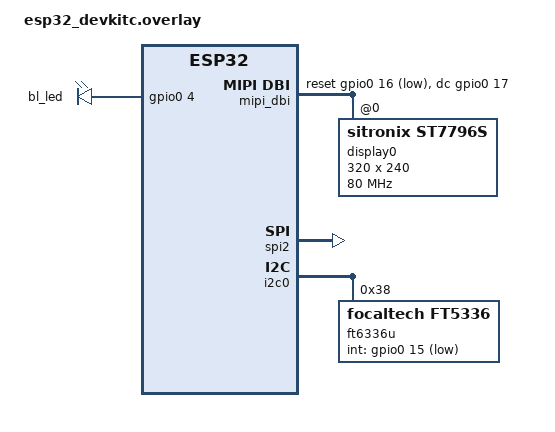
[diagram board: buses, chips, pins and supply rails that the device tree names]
/* Auto-generated by @typecad/framework-zephyr from cuttlefish.config.ts. */
/* Enables peripherals the program uses. West merges this over the board DT. */

&spi2 {
    status = "okay";
};

/ {
    mipi_dbi: mipi-dbi {
        compatible = "zephyr,mipi-dbi-spi";
        spi-dev = <&spi2>;
        dc-gpios = <&gpio0 17 GPIO_ACTIVE_HIGH>;
        reset-gpios = <&gpio0 16 GPIO_ACTIVE_LOW>;
        write-only;
        #address-cells = <1>;
        #size-cells = <0>;
        display0: display@0 {
            compatible = "sitronix,st7796s";
            reg = <0>;
            mipi-max-frequency = <80000000>;
            mipi-mode = "MIPI_DBI_MODE_SPI_4WIRE";
            width = <320>;
            height = <240>;
            pgc = [f0 09 0b 06 04 2e 46 46 39 13 15 12 15 12 12];
            ngc = [f0 09 0b 06 04 2e 46 46 39 13 15 12 15 12 12];
        };
    };
};

/ {
    aliases {
        backlight = &bl_led;
    };
    bl_gpio: bl-gpio-leds {
        compatible = "gpio-leds";
        bl_led: led {
            gpios = <&gpio0 4 GPIO_ACTIVE_HIGH>;
        };
    };
};

&i2c0 {
    status = "okay";
    ft6336u: ft6336u@38 {
        compatible = "focaltech,ft5336";
        reg = <0x38>;
        int-gpios = <&gpio0 15 GPIO_ACTIVE_LOW>;
    };
};
